# CTRL_MMR0_CTRL_MMR0_PWR_MMRS_09280000h register map
Vendor: Texas Instruments
Peripheral module from a debugger description file (folder am62L).
Registers are 32-bit, read-only, reset values left out (the file's numbers can be read two ways) unless marked. A register's access mark holds for its fields unless they carry their own. Offsets are as the file gives them; lines under a group give offsets from that group; [hi:lo] are bit positions; {n}, {i} and the like mark numbered series; 'fields as' and 'values as' point back to an identical list; <NAME> marks a mode.

## CTRL_MMR0_PWR_MMRS
0x1010 CTRL_MMR0_PWR_MMRS_RST_STAT — Reset Status
  [0] RST_STAT_RESET_ISO_DONE_Z — Reset Source: mod_por_rst_n
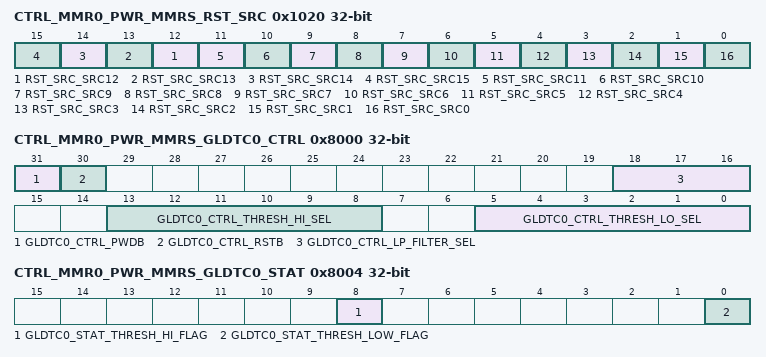
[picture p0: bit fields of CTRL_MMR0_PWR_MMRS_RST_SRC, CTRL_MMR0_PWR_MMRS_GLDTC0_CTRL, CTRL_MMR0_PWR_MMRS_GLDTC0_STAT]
0x1020 CTRL_MMR0_PWR_MMRS_RST_SRC — Captures Reason for Warm and Main Domain Power On ResetsRead Only Mirror of WKUP CTRL MMR version
  [n] RST_SRC_SRC{n} (n=12..15) — reserved Reset Source: mod_por_rst_n
  [11] RST_SRC_SRC11 — DDRSS Timeout Reset Reset Source: mod_por_rst_n
  [10] RST_SRC_SRC10 — Debug Subsystem Initiated Reset Reset Source: mod_por_rst_n
  [9] RST_SRC_SRC9 — Thermal Reset Reset Source: mod_por_rst_n
  [8] RST_SRC_SRC8 — reserved Reset Source: mod_por_rst_n
  [7] RST_SRC_SRC7 — reserved Reset Source: mod_por_rst_n
  [6] RST_SRC_SRC6 — reserved Reset Source: mod_por_rst_n
  [5] RST_SRC_SRC5 — Reset Caused by Watchdog 1 Reset Source: mod_por_rst_n
  [4] RST_SRC_SRC4 — Reset Caused by Watchdog 0 Reset Source: mod_por_rst_n
  [3] RST_SRC_SRC3 — Reset Caused by SMS (Warm Reset) Reset Source: mod_por_rst_n
  [2] RST_SRC_SRC2 — Reset Caused by SMS (Cold Reset) Reset Source: mod_por_rst_n
  [1] RST_SRC_SRC1 — Reset caused by SW_WARMRESET Request Reset Source: mod_por_rst_n
  [0] RST_SRC_SRC0 — Reset caused by RESETz pin assertion Reset Source: mod_por_rst_n
0x8000 CTRL_MMR0_PWR_MMRS_GLDTC0_CTRL rw — Controls Sensitivity of the Power Glitch Detection Ip
  [31] GLDTC0_CTRL_PWDB — Power down - active low. Field values (others are reserved):1'b0 - Power Down Glitch Detector1'b1 - Power Up Glitch Detector Reset Source: mod_por_rst_n
  [30] GLDTC0_CTRL_RSTB — Reset - active low. To ensure proper operation, rstb must be not be de-asserted for at least 100 ns after power-up (pwdb de-asserted). Additionally, rstb must be toggled low at least 200 ns after any change in threshold or low-pass filter settings to prevent abnormal trigger events.Field values (others are reserved):1'b0 - Reset Glitch Detector1'b1 - Glitch Detector Active Reset Source: mod_por_rst_n
  [18:16] GLDTC0_CTRL_LP_FILTER_SEL — Selects the glitch detect low-pass filter bandwidthField values (others are reserved):3'b000 - 150 kHz3'b001 - 125 kHz3'b010 - 100 kHz3'b011 - 80 kHz3'b100 - 60 kHz3'b101 - 45 kHz3'b110 - 30 kHz3'b111 - 15 kHz Reset Source: mod_por_rst_n
  [13:8] GLDTC0_CTRL_THRESH_HI_SEL — Selects the high voltage glitch threshold as a percentage of the monitored voltageField values (others are reserved):6'b000000 - 93.5% of VDD6'b000001 - 94.0% of VDD6'b000010 - 94.5% of VDD6'b000011 - 95.0% of VDD6'b000100 - 95.5% of VDD6'b000101 - 96.0% of VDD6'b000110 - 96.5% of VDD6'b000111 - 97.0% of VDD6'b001000 - 97.5% of VDD6'b001001 - 98.0% of VDD6'b001010 - 98.5% of VDD6'b001011 - 99.0% of VDD6'b001100 - 99.5% of VDD6'b001101 - 100.0% of VDD6'b001110 - 100.5% of VDD6'b001111 - 101.0% of VDD6'b010000 - 101.5% of VDD6'b010001 - 102.0% of VDD6'b010010 - 102.5% of VDD6'b010011 - 103.0% of VDD6'b010100 - 103.5% of VDD6'b010101 - 104.0% of VDD6'b010110 - 104.5% of VDD6'b010111 - 105.0% of VDD6'b011000 - 105.5% of VDD6'b011001 - 106.0% of VDD6'b011010 - 106.5% of VDD6'b011011 - 107.0% of VDD6'b011100 - 107.5% of VDD6'b011101 - 108.0% of VDD6'b011110 - 108.5% of VDD6'b011111 - 109.0% of VDD6'b100000 - 109.5% of VDD6'b100001 - 110.0% of VDD6'b100010 - 111.0% of VDD6'b100011 - 112.0% of VDD6'b100100 - 113.0% of VDD6'b100101 - 114.0% of VDD6'b100110 - 115.0% of VDD6'b100111 - 116.0% of VDD6'b101000 - 117.0% of VDD6'b101001 - 118.0% of VDD6'b101010 - 119.0% of VDD6'b101011 - 120.0% of VDD6'b101100 - 121.0% of VDD6'b101101 - 122.0% of VDD6'b101110 - 123.0% of VDD6'b101111 - 124.0% of VDD6'b110000 - 125.0% of VDD6'b110001 - 126.0% of VDD6'b110010 - 127.0% of VDD6'b110011 - 128.0% of VDD6'b110100 - 129.0% of VDD6'b110101 - 130.0% of VDD6'b110110 - 131.0% of VDD6'b110111 - 132.0% of VDD6'b111000 - 133.0% of VDD6'b111001 - 134.0% of VDD6'b111010 - 135.0% of VDD6'b111011 - 136.0% of VDD6'b111100 - 137.0% of VDD6'b111101 - 138.0% of VDD6'b111110 - 139.0% of VDD6'b111111 - 140.0% of VDD Reset Source: mod_por_rst_n
  [5:0] GLDTC0_CTRL_THRESH_LO_SEL — Selects the low voltage glitch threshold as a percentage of the monitored voltageField values (others are reserved):6'b000000 - 106.5% of VDD6'b000001 - 106.0% of VDD6'b000010 - 105.5% of VDD6'b000011 - 105.0% of VDD6'b000100 - 104.5% of VDD6'b000101 - 104.0% of VDD6'b000110 - 103.5% of VDD6'b000111 - 103.0% of VDD6'b001000 - 102.5% of VDD6'b001001 - 102.0% of VDD6'b001010 - 101.5% of VDD6'b001011 - 101.0% of VDD6'b001100 - 100.5% of VDD6'b001101 - 100.0% of VDD6'b001110 - 99.5% of VDD6'b001111 - 99.0% of VDD6'b010000 - 98.5% of VDD6'b010001 - 98.0% of VDD6'b010010 - 97.5% of VDD6'b010011 - 97.0% of VDD6'b010100 - 96.5% of VDD6'b010101 - 96.0% of VDD6'b010110 - 95.5% of VDD6'b010111 - 95.0% of VDD6'b011000 - 94.5% of VDD6'b011001 - 94.0% of VDD6'b011010 - 93.5% of VDD6'b011011 - 93.0% of VDD6'b011100 - 92.5% of VDD6'b011101 - 92.0% of VDD6'b011110 - 91.5% of VDD6'b011111 - 91.0% of VDD6'b100000 - 90.5% of VDD6'b100001 - 90.0% of VDD6'b100010 - 89.0% of VDD6'b100011 - 88.0% of VDD6'b100100 - 87.0% of VDD6'b100101 - 86.0% of VDD6'b100110 - 85.0% of VDD6'b100111 - 84.0% of VDD6'b101000 - 83.0% of VDD6'b101001 - 82.0% of VDD6'b101010 - 81.0% of VDD6'b101011 - 80.0% of VDD6'b101100 - 79.0% of VDD6'b101101 - 78.0% of VDD6'b101110 - 77.0% of VDD6'b101111 - 76.0% of VDD6'b110000 - 75.0% of VDD6'b110001 - 74.0% of VDD6'b110010 - 73.0% of VDD6'b110011 - 72.0% of VDD6'b110100 - 71.0% of VDD6'b110101 - 70.0% of VDD6'b110110 - 69.0% of VDD6'b110111 - 68.0% of VDD6'b111000 - 67.0% of VDD6'b111001 - 66.0% of VDD6'b111010 - 65.0% of VDD6'b111011 - 64.0% of VDD6'b111100 - 63.0% of VDD6'b111101 - 62.0% of VDD6'b111110 - 61.0% of VDD6'b111111 - 60.0% of VDD Reset Source: mod_por_rst_n
0x8004 CTRL_MMR0_PWR_MMRS_GLDTC0_STAT — Status of the Power Glitch Detection Ip
  [8] GLDTC0_STAT_THRESH_HI_FLAG — High voltage flag. This flag is cleared by clearing the GLDTC0_CTRL rstb bit.Field values (others are reserved):1'b0 - Low Threshold Violation Not Detected1'b1 - Low Threshold Violation Detected Reset Source: mod_por_rst_n
  [0] GLDTC0_STAT_THRESH_LOW_FLAG — Low voltage flag. This flag is cleared by clearing the GLDTC0_CTRL rstb bit.Field values (others are reserved):1'b0 - Low Threshold Violation Not Detected1'b1 - Low Threshold Violation Detected Reset Source: mod_por_rst_n
